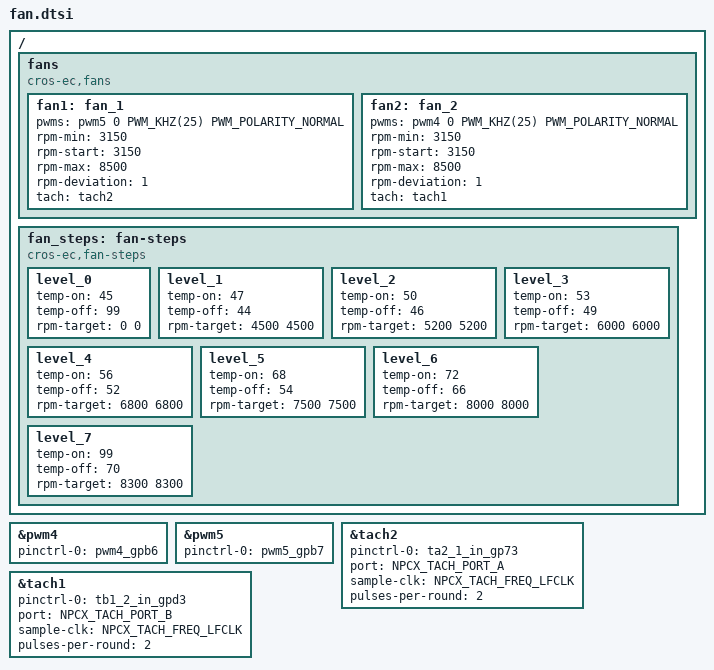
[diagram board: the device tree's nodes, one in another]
/* Copyright 2026 The ChromiumOS Authors
 * Use of this source code is governed by a BSD-style license that can be
 * found in the LICENSE file.
 */

/ {
	fans {
		compatible = "cros-ec,fans";

		fan1: fan_1 {
			pwms = <&pwm5 0 PWM_KHZ(25) PWM_POLARITY_NORMAL>;
			rpm-min = <3150>;
			rpm-start = <3150>;
			rpm-max = <8500>;
			rpm-deviation = <1>;
			tach = <&tach2>;
		};
		fan2: fan_2 {
			pwms = <&pwm4 0 PWM_KHZ(25) PWM_POLARITY_NORMAL>;
			rpm-min = <3150>;
			rpm-start = <3150>;
			rpm-max = <8500>;
			rpm-deviation = <1>;
			tach = <&tach1>;
		};
	};

	fan_steps: fan-steps {
		compatible = "cros-ec,fan-steps";
		level_0 {
			temp-on = <45>;
			temp-off = <99>;
			rpm-target = <0 0>;
		};
		level_1 {
			temp-on = <47>;
			temp-off = <44>;
			rpm-target = <4500 4500>;
		};
		level_2 {
			temp-on = <50>;
			temp-off = <46>;
			rpm-target = <5200 5200>;
		};
		level_3 {
			temp-on = <53>;
			temp-off = <49>;
			rpm-target = <6000 6000>;
		};
		level_4 {
			temp-on = <56>;
			temp-off = <52>;
			rpm-target = <6800 6800>;
		};
		level_5 {
			temp-on = <68>;
			temp-off = <54>;
			rpm-target = <7500 7500>;
		};
		level_6 {
			temp-on = <72>;
			temp-off = <66>;
			rpm-target = <8000 8000>;
		};
		level_7 {
			temp-on = <99>;
			temp-off = <70>;
			rpm-target = <8300 8300>;
		};
	};
};

&pwm4 {
	status = "okay";
	pinctrl-0 = <&pwm4_gpb6>;
	pinctrl-names = "default";
};

&pwm5 {
	status = "okay";
	pinctrl-0 = <&pwm5_gpb7>;
	pinctrl-names = "default";
};

&tach2 {
	status = "okay";
	pinctrl-0 = <&ta2_1_in_gp73>;
	pinctrl-names = "default";
	port = <NPCX_TACH_PORT_A>;
	sample-clk = <NPCX_TACH_FREQ_LFCLK>;
	pulses-per-round = <2>;
};

&tach1 {
	status = "okay";
	pinctrl-0 = <&tb1_2_in_gpd3>;
	pinctrl-names = "default";
	port = <NPCX_TACH_PORT_B>;
	sample-clk = <NPCX_TACH_FREQ_LFCLK>;
	pulses-per-round = <2>;
};
